AUTOSAR XML (schema 4-2-2)
package /ComponentTypes
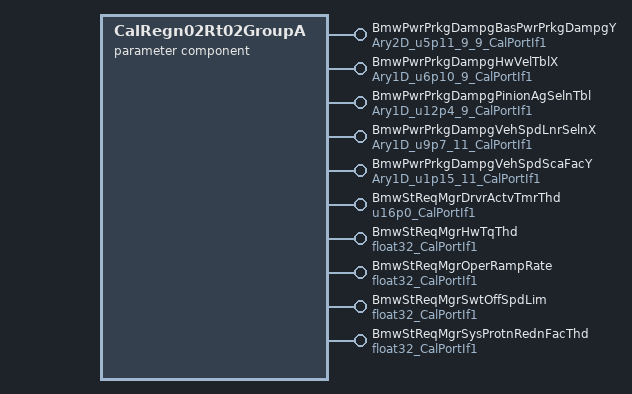
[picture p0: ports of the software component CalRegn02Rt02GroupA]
  parameter sw component type CalRegn02Rt02GroupA
    10 x provide port:
      BmwPwrPrkgDampgBasPwrPrkgDampgY: parameter-provide-com-spec{init-value=[[0, 0, 0, 0, 205, 410, 614, 819, 1024], [0, 0, 0, 0, 205, 410, 614, 819, 1024], [0, 0, 0, 0, 205, 410, 614, 819, 1024], [0, 0, 0, 0, 205, 410, 614, 819, 1024], [0, 0, 0, 0, 205, 410, 614, 819, 1024], [0, 0, 0, 0, 205, 410, 614, 819, 1024], [0, 0, 0, 0, 205, 410, 614, 819, 1024], [0, 0, 0, 0, 154, 307, 471, 604, 819], [0, 0, 0, 0, 20, 41, 61, 82, 102]], parameter=Ary2D}, provided-interface=Ary2D_u5p11_9_9_CalPortIf1
      BmwPwrPrkgDampgHwVelTblX: parameter-provide-com-spec{init-value=[0, 1280, 2560, 3840, 5120, 6400, 7680, 8960, 10240], parameter=Ary1D}, provided-interface=Ary1D_u6p10_9_CalPortIf1
      BmwPwrPrkgDampgPinionAgSelnTbl: parameter-provide-com-spec{init-value=[0, 1200, 2400, 3600, 4800, 6000, 7200, 8400, 9600], parameter=Ary1D}, provided-interface=Ary1D_u12p4_9_CalPortIf1
      BmwPwrPrkgDampgVehSpdLnrSelnX: parameter-provide-com-spec{init-value=[0, 256, 512, 768, 1024, 1280, 1536, 1792, 2048, 2304, 2560], parameter=Ary1D}, provided-interface=Ary1D_u9p7_11_CalPortIf1
      BmwPwrPrkgDampgVehSpdScaFacY: parameter-provide-com-spec{init-value=[32768, 32768, 32768, 32768, 32768, 32768, 26214, 19661, 13107, 6554, 0], parameter=Ary1D}, provided-interface=Ary1D_u1p15_11_CalPortIf1
      BmwStReqMgrDrvrActvTmrThd: parameter-provide-com-spec{init-value=500, parameter=Val}, provided-interface=u16p0_CalPortIf1
      BmwStReqMgrHwTqThd: parameter-provide-com-spec{init-value=0.4, parameter=Val}, provided-interface=float32_CalPortIf1
      BmwStReqMgrOperRampRate: parameter-provide-com-spec{init-value=1, parameter=Val}, provided-interface=float32_CalPortIf1
      BmwStReqMgrSwtOffSpdLim: parameter-provide-com-spec{init-value=10, parameter=Val}, provided-interface=float32_CalPortIf1
      BmwStReqMgrSysProtnRednFacThd: parameter-provide-com-spec{init-value=0.3, parameter=Val}, provided-interface=float32_CalPortIf1
